# MSS_CTRL_MSS_CTRL_50D00000h register map
Vendor: Texas Instruments
Registers are 32-bit, read-write, reset values left out (the file's numbers can be read two ways) unless marked. A register's access mark holds for its fields unless they carry their own. Offsets are as the file gives them; [hi:lo] are bit positions.

## MSS_CTRL (part 6 of 6)
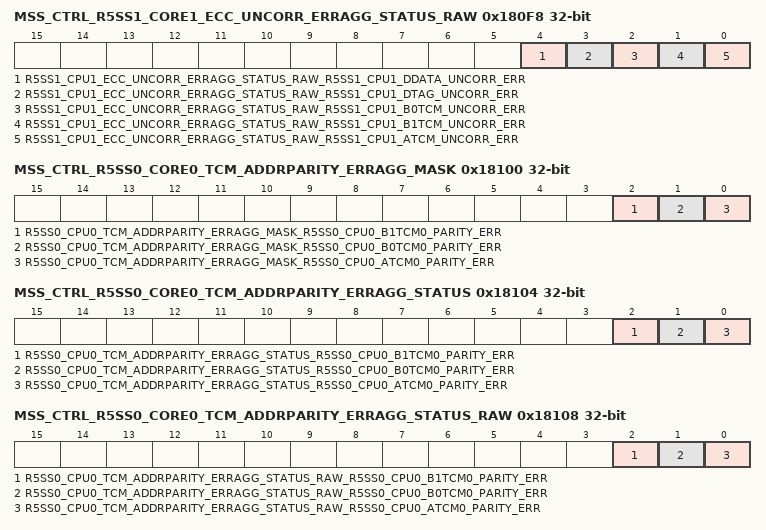
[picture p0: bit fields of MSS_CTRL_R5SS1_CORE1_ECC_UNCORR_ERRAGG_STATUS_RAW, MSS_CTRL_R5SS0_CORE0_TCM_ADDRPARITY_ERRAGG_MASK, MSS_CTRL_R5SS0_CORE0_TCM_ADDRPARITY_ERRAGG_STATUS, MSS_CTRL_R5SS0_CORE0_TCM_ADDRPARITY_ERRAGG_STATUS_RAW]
0x180F8 MSS_CTRL_R5SS1_CORE1_ECC_UNCORR_ERRAGG_STATUS_RAW
  [4] R5SS1_CPU1_ECC_UNCORR_ERRAGG_STATUS_RAW_R5SS1_CPU1_DDATA_UNCORR_ERR — Raw Status of Interrupt from correctable error of corresponding CPUSet only if Interupt is unmasked in corresponding R5SS*_CPU*_ECC_UNCORR_ERRAGG_MASK registerWrie 0x1 to clear this interrupt.
  [3] R5SS1_CPU1_ECC_UNCORR_ERRAGG_STATUS_RAW_R5SS1_CPU1_DTAG_UNCORR_ERR — Raw Status of Interrupt from correctable error of corresponding CPUSet only if Interupt is unmasked in corresponding R5SS*_CPU*_ECC_UNCORR_ERRAGG_MASK registerWrie 0x1 to clear this interrupt.
  [2] R5SS1_CPU1_ECC_UNCORR_ERRAGG_STATUS_RAW_R5SS1_CPU1_B0TCM_UNCORR_ERR — Raw Status of Interrupt from correctable error of corresponding CPUSet only if Interupt is unmasked in corresponding R5SS*_CPU*_ECC_UNCORR_ERRAGG_MASK registerWrie 0x1 to clear this interrupt.
  [1] R5SS1_CPU1_ECC_UNCORR_ERRAGG_STATUS_RAW_R5SS1_CPU1_B1TCM_UNCORR_ERR — Raw Status of Interrupt from correctable error of corresponding CPUSet only if Interupt is unmasked in corresponding R5SS*_CPU*_ECC_UNCORR_ERRAGG_MASK registerWrie 0x1 to clear this interrupt.
  [0] R5SS1_CPU1_ECC_UNCORR_ERRAGG_STATUS_RAW_R5SS1_CPU1_ATCM_UNCORR_ERR — Raw Status of Interrupt from correctable error of corresponding CPUSet only if Interupt is unmasked in corresponding R5SS*_CPU*_ECC_UNCORR_ERRAGG_MASK registerWrie 0x1 to clear this interrupt.
0x18100 MSS_CTRL_R5SS0_CORE0_TCM_ADDRPARITY_ERRAGG_MASK
  [2] R5SS0_CPU0_TCM_ADDRPARITY_ERRAGG_MASK_R5SS0_CPU0_B1TCM0_PARITY_ERR — Mask Interrupt for address parity error s to aggregated Interrupt of corresponding CPU1'b1 : Interrupt is Masked1'b0 : Interrupt is Unmasked
  [1] R5SS0_CPU0_TCM_ADDRPARITY_ERRAGG_MASK_R5SS0_CPU0_B0TCM0_PARITY_ERR — Mask Interrupt for address parity error s to aggregated Interrupt of corresponding CPU1'b1 : Interrupt is Masked1'b0 : Interrupt is Unmasked
  [0] R5SS0_CPU0_TCM_ADDRPARITY_ERRAGG_MASK_R5SS0_CPU0_ATCM0_PARITY_ERR — Mask Interrupt for address parity error s to aggregated Interrupt of corresponding CPU1'b1 : Interrupt is Masked1'b0 : Interrupt is Unmasked
0x18104 MSS_CTRL_R5SS0_CORE0_TCM_ADDRPARITY_ERRAGG_STATUS
  [2] R5SS0_CPU0_TCM_ADDRPARITY_ERRAGG_STATUS_R5SS0_CPU0_B1TCM0_PARITY_ERR — Status of Interrupt from address parity error of corresponding CPU*_TCM_ADDRPARITY_ERRAGG_MASK registerWrie 0x1 to clear this interrupt.
  [1] R5SS0_CPU0_TCM_ADDRPARITY_ERRAGG_STATUS_R5SS0_CPU0_B0TCM0_PARITY_ERR — Status of Interrupt from address parity error of corresponding CPU*_TCM_ADDRPARITY_ERRAGG_MASK registerWrie 0x1 to clear this interrupt.
  [0] R5SS0_CPU0_TCM_ADDRPARITY_ERRAGG_STATUS_R5SS0_CPU0_ATCM0_PARITY_ERR — Status of Interrupt from address parity error of corresponding CPU*_TCM_ADDRPARITY_ERRAGG_MASK registerWrie 0x1 to clear this interrupt.
0x18108 MSS_CTRL_R5SS0_CORE0_TCM_ADDRPARITY_ERRAGG_STATUS_RAW
  [2] R5SS0_CPU0_TCM_ADDRPARITY_ERRAGG_STATUS_RAW_R5SS0_CPU0_B1TCM0_PARITY_ERR — Raw Status of Interrupt from address parity error of corresponding CPU*_TCM_ADDRPARITY_ERRAGG_MASK registerWrie 0x1 to clear this interrupt.
  [1] R5SS0_CPU0_TCM_ADDRPARITY_ERRAGG_STATUS_RAW_R5SS0_CPU0_B0TCM0_PARITY_ERR — Raw Status of Interrupt from address parity error of corresponding CPU*_TCM_ADDRPARITY_ERRAGG_MASK registerWrie 0x1 to clear this interrupt.
  [0] R5SS0_CPU0_TCM_ADDRPARITY_ERRAGG_STATUS_RAW_R5SS0_CPU0_ATCM0_PARITY_ERR — Raw Status of Interrupt from address parity error of corresponding CPU*_TCM_ADDRPARITY_ERRAGG_MASK registerWrie 0x1 to clear this interrupt.
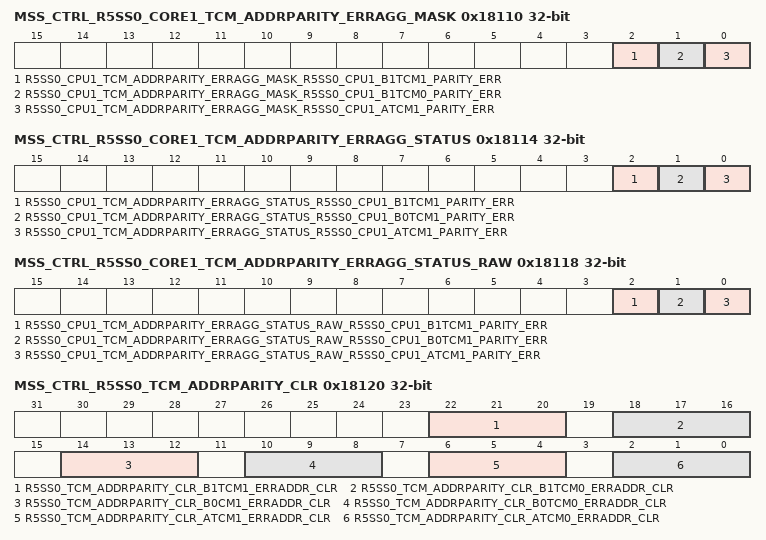
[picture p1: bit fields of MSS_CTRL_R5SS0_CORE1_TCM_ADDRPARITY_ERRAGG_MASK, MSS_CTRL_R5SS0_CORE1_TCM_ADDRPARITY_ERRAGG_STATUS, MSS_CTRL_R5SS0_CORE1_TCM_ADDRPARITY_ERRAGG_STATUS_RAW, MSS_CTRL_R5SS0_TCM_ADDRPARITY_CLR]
0x18110 MSS_CTRL_R5SS0_CORE1_TCM_ADDRPARITY_ERRAGG_MASK
  [2] R5SS0_CPU1_TCM_ADDRPARITY_ERRAGG_MASK_R5SS0_CPU1_B1TCM1_PARITY_ERR — Mask Interrupt for address parity error s to aggregated Interrupt of corresponding CPU1'b1 : Interrupt is Masked1'b0 : Interrupt is Unmasked
  [1] R5SS0_CPU1_TCM_ADDRPARITY_ERRAGG_MASK_R5SS0_CPU1_B1TCM0_PARITY_ERR — Mask Interrupt for address parity error s to aggregated Interrupt of corresponding CPU1'b1 : Interrupt is Masked1'b0 : Interrupt is Unmasked
  [0] R5SS0_CPU1_TCM_ADDRPARITY_ERRAGG_MASK_R5SS0_CPU1_ATCM1_PARITY_ERR — Mask Interrupt for address parity error s to aggregated Interrupt of corresponding CPU1'b1 : Interrupt is Masked1'b0 : Interrupt is Unmasked
0x18114 MSS_CTRL_R5SS0_CORE1_TCM_ADDRPARITY_ERRAGG_STATUS
  [2] R5SS0_CPU1_TCM_ADDRPARITY_ERRAGG_STATUS_R5SS0_CPU1_B1TCM1_PARITY_ERR — Status of Interrupt from address parity error of corresponding CPU*_TCM_ADDRPARITY_ERRAGG_MASK registerWrie 0x1 to clear this interrupt.
  [1] R5SS0_CPU1_TCM_ADDRPARITY_ERRAGG_STATUS_R5SS0_CPU1_B0TCM1_PARITY_ERR — Status of Interrupt from address parity error of corresponding CPU*_TCM_ADDRPARITY_ERRAGG_MASK registerWrie 0x1 to clear this interrupt.
  [0] R5SS0_CPU1_TCM_ADDRPARITY_ERRAGG_STATUS_R5SS0_CPU1_ATCM1_PARITY_ERR — Status of Interrupt from address parity error of corresponding CPU*_TCM_ADDRPARITY_ERRAGG_MASK registerWrie 0x1 to clear this interrupt.
0x18118 MSS_CTRL_R5SS0_CORE1_TCM_ADDRPARITY_ERRAGG_STATUS_RAW
  [2] R5SS0_CPU1_TCM_ADDRPARITY_ERRAGG_STATUS_RAW_R5SS0_CPU1_B1TCM1_PARITY_ERR — Raw Status of Interrupt from address parity error of corresponding CPU*_TCM_ADDRPARITY_ERRAGG_MASK registerWrie 0x1 to clear this interrupt.
  [1] R5SS0_CPU1_TCM_ADDRPARITY_ERRAGG_STATUS_RAW_R5SS0_CPU1_B0TCM1_PARITY_ERR — Raw Status of Interrupt from address parity error of corresponding CPU*_TCM_ADDRPARITY_ERRAGG_MASK registerWrie 0x1 to clear this interrupt.
  [0] R5SS0_CPU1_TCM_ADDRPARITY_ERRAGG_STATUS_RAW_R5SS0_CPU1_ATCM1_PARITY_ERR — Raw Status of Interrupt from address parity error of corresponding CPU*_TCM_ADDRPARITY_ERRAGG_MASK registerWrie 0x1 to clear this interrupt.
0x18120 MSS_CTRL_R5SS0_TCM_ADDRPARITY_CLR
  [22:20] R5SS0_TCM_ADDRPARITY_CLR_B1TCM1_ERRADDR_CLR — Write pulse bit field:Writing 3'b111 clears the Address latched after parity error for B1TCM of CR5B
  [18:16] R5SS0_TCM_ADDRPARITY_CLR_B1TCM0_ERRADDR_CLR — Write pulse bit field:Writing 3'b111 clears the Address latched after parity error for B1TCM of CR5A
  [14:12] R5SS0_TCM_ADDRPARITY_CLR_B0CM1_ERRADDR_CLR — Write pulse bit field:Writing 3'b111 clears the Address latched after parity error for B0TCM of CR5B
  [10:8] R5SS0_TCM_ADDRPARITY_CLR_B0TCM0_ERRADDR_CLR — Write pulse bit field:Writing 3'b111 clears the Address latched after parity error for B0TCM of CR5A
  [6:4] R5SS0_TCM_ADDRPARITY_CLR_ATCM1_ERRADDR_CLR — Write pulse bit field:Writing 3'b111 clears the Address latched after parity error for ATCM of CR5B
  [2:0] R5SS0_TCM_ADDRPARITY_CLR_ATCM0_ERRADDR_CLR — Pulse bit-field Writing 3'b111 clears the Address latched after parity error for ATCM of CR5A
0x18124 MSS_CTRL_R5SS0_CORE0_ADDRPARITY_ERR_ATCM ro
  [19:0] R5SS0_CORE0_ADDRPARITY_ERR_ATCM_ADDR — Address lathched when parity error is occurred for ATCM of CR5A
0x18128 MSS_CTRL_R5SS0_CORE1_ADDRPARITY_ERR_ATCM ro
  [19:0] R5SS0_CORE1_ADDRPARITY_ERR_ATCM_ADDR — Address lathched when parity error is occurred for ATCM of CR5B
0x1812C MSS_CTRL_R5SS0_CORE0_ERR_ADDRPARITY_B0TCM ro
  [19:0] R5SS0_CORE0_ERR_ADDRPARITY_B0TCM_ADDR — Address lathched when parity error is occurred for B0TCM of CR5A
0x18130 MSS_CTRL_R5SS0_CORE1_ERR_ADDRPARITY_B0TCM ro
  [19:0] R5SS0_CORE1_ERR_ADDRPARITY_B0TCM_ADDR — Address lathched when parity error is occurred for B0TCM of CR5B
0x18134 MSS_CTRL_R5SS0_CORE0_ERR_ADDRPARITY_B1TCM ro
  [19:0] R5SS0_CORE0_ERR_ADDRPARITY_B1TCM_ADDR — Address lathched when parity error is occurred for B1TCM of CR5A
0x18138 MSS_CTRL_R5SS0_CORE1_ERR_ADDRPARITY_B1TCM ro
  [19:0] R5SS0_CORE1_ERR_ADDRPARITY_B1TCM_ADDR — Address lathched when parity error is occurred for B1TCM of CR5B
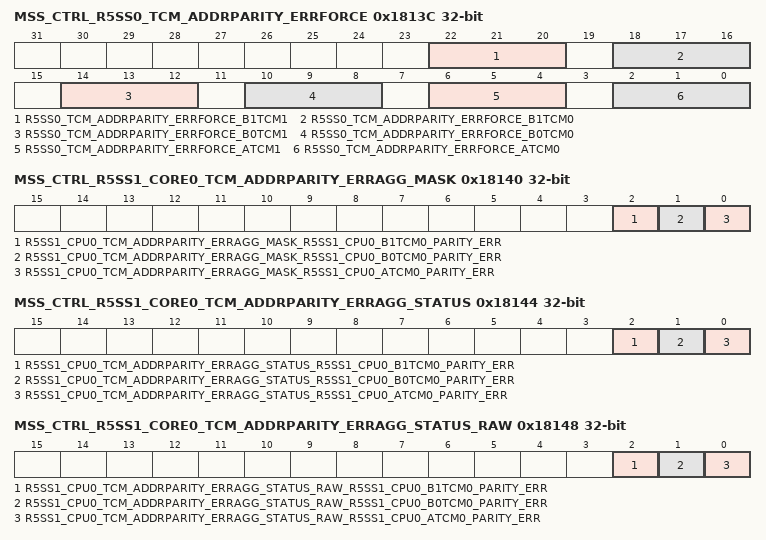
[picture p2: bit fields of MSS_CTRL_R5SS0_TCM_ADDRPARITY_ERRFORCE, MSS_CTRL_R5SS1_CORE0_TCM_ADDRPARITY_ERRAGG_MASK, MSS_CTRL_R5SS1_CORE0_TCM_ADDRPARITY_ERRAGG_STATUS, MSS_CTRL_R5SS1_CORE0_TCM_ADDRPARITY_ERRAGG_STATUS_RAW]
0x1813C MSS_CTRL_R5SS0_TCM_ADDRPARITY_ERRFORCE
  [22:20] R5SS0_TCM_ADDRPARITY_ERRFORCE_B1TCM1 — Write pulse bit field:Writing 3'b111 forces a parity error for B1TCM of CR5B
  [18:16] R5SS0_TCM_ADDRPARITY_ERRFORCE_B1TCM0 — Write pulse bit field:Writing 3'b111 forces a parity error for B1TCM of CR5A
  [14:12] R5SS0_TCM_ADDRPARITY_ERRFORCE_B0TCM1 — Write pulse bit field:Writing 3'b111 forces a parity error for B0TCM of CR5B
  [10:8] R5SS0_TCM_ADDRPARITY_ERRFORCE_B0TCM0 — Write pulse bit field:Writing 3'b111 forces a parity error for B0TCM of CR5A
  [6:4] R5SS0_TCM_ADDRPARITY_ERRFORCE_ATCM1 — Write pulse bit field:Writing 3'b111 forces a parity error for ATCM of CR5B
  [2:0] R5SS0_TCM_ADDRPARITY_ERRFORCE_ATCM0 — Write pulse bit field:Writing 3'b111 forces a parity error for ATCM of CR5A
0x18140 MSS_CTRL_R5SS1_CORE0_TCM_ADDRPARITY_ERRAGG_MASK
  [2] R5SS1_CPU0_TCM_ADDRPARITY_ERRAGG_MASK_R5SS1_CPU0_B1TCM0_PARITY_ERR — Mask Interrupt for address parity error s to aggregated Interrupt of corresponding CPU1'b1 : Interrupt is Masked1'b0 : Interrupt is Unmasked
  [1] R5SS1_CPU0_TCM_ADDRPARITY_ERRAGG_MASK_R5SS1_CPU0_B0TCM0_PARITY_ERR — Mask Interrupt for address parity error s to aggregated Interrupt of corresponding CPU1'b1 : Interrupt is Masked1'b0 : Interrupt is Unmasked
  [0] R5SS1_CPU0_TCM_ADDRPARITY_ERRAGG_MASK_R5SS1_CPU0_ATCM0_PARITY_ERR — Mask Interrupt for address parity error s to aggregated Interrupt of corresponding CPU1'b1 : Interrupt is Masked1'b0 : Interrupt is Unmasked
0x18144 MSS_CTRL_R5SS1_CORE0_TCM_ADDRPARITY_ERRAGG_STATUS
  [2] R5SS1_CPU0_TCM_ADDRPARITY_ERRAGG_STATUS_R5SS1_CPU0_B1TCM0_PARITY_ERR — Status of Interrupt from address parity error of corresponding CPU*_TCM_ADDRPARITY_ERRAGG_MASK registerWrie 0x1 to clear this interrupt.
  [1] R5SS1_CPU0_TCM_ADDRPARITY_ERRAGG_STATUS_R5SS1_CPU0_B0TCM0_PARITY_ERR — Status of Interrupt from address parity error of corresponding CPU*_TCM_ADDRPARITY_ERRAGG_MASK registerWrie 0x1 to clear this interrupt.
  [0] R5SS1_CPU0_TCM_ADDRPARITY_ERRAGG_STATUS_R5SS1_CPU0_ATCM0_PARITY_ERR — Status of Interrupt from address parity error of corresponding CPU*_TCM_ADDRPARITY_ERRAGG_MASK registerWrie 0x1 to clear this interrupt.
0x18148 MSS_CTRL_R5SS1_CORE0_TCM_ADDRPARITY_ERRAGG_STATUS_RAW
  [2] R5SS1_CPU0_TCM_ADDRPARITY_ERRAGG_STATUS_RAW_R5SS1_CPU0_B1TCM0_PARITY_ERR — Raw Status of Interrupt from address parity error of corresponding CPU*_TCM_ADDRPARITY_ERRAGG_MASK registerWrie 0x1 to clear this interrupt.
  [1] R5SS1_CPU0_TCM_ADDRPARITY_ERRAGG_STATUS_RAW_R5SS1_CPU0_B0TCM0_PARITY_ERR — Raw Status of Interrupt from address parity error of corresponding CPU*_TCM_ADDRPARITY_ERRAGG_MASK registerWrie 0x1 to clear this interrupt.
  [0] R5SS1_CPU0_TCM_ADDRPARITY_ERRAGG_STATUS_RAW_R5SS1_CPU0_ATCM0_PARITY_ERR — Raw Status of Interrupt from address parity error of corresponding CPU*_TCM_ADDRPARITY_ERRAGG_MASK registerWrie 0x1 to clear this interrupt.
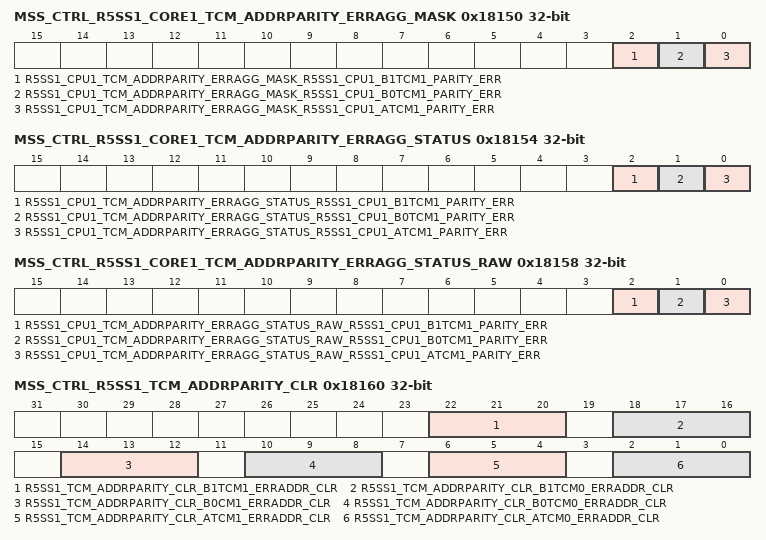
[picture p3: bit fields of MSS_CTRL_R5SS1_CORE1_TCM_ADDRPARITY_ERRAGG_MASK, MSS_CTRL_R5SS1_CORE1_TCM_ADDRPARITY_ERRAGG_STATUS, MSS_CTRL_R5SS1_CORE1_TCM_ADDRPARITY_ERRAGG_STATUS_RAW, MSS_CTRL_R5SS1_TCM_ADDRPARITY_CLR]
0x18150 MSS_CTRL_R5SS1_CORE1_TCM_ADDRPARITY_ERRAGG_MASK
  [2] R5SS1_CPU1_TCM_ADDRPARITY_ERRAGG_MASK_R5SS1_CPU1_B1TCM1_PARITY_ERR — Mask Interrupt for address parity error s to aggregated Interrupt of corresponding CPU1'b1 : Interrupt is Masked1'b0 : Interrupt is Unmasked
  [1] R5SS1_CPU1_TCM_ADDRPARITY_ERRAGG_MASK_R5SS1_CPU1_B0TCM1_PARITY_ERR — Mask Interrupt for address parity error s to aggregated Interrupt of corresponding CPU1'b1 : Interrupt is Masked1'b0 : Interrupt is Unmasked
  [0] R5SS1_CPU1_TCM_ADDRPARITY_ERRAGG_MASK_R5SS1_CPU1_ATCM1_PARITY_ERR — Mask Interrupt for address parity error s to aggregated Interrupt of corresponding CPU1'b1 : Interrupt is Masked1'b0 : Interrupt is Unmasked
0x18154 MSS_CTRL_R5SS1_CORE1_TCM_ADDRPARITY_ERRAGG_STATUS
  [2] R5SS1_CPU1_TCM_ADDRPARITY_ERRAGG_STATUS_R5SS1_CPU1_B1TCM1_PARITY_ERR — Status of Interrupt from address parity error of corresponding CPU*_TCM_ADDRPARITY_ERRAGG_MASK registerWrie 0x1 to clear this interrupt.
  [1] R5SS1_CPU1_TCM_ADDRPARITY_ERRAGG_STATUS_R5SS1_CPU1_B0TCM1_PARITY_ERR — Status of Interrupt from address parity error of corresponding CPU*_TCM_ADDRPARITY_ERRAGG_MASK registerWrie 0x1 to clear this interrupt.
  [0] R5SS1_CPU1_TCM_ADDRPARITY_ERRAGG_STATUS_R5SS1_CPU1_ATCM1_PARITY_ERR — Status of Interrupt from address parity error of corresponding CPU*_TCM_ADDRPARITY_ERRAGG_MASK registerWrie 0x1 to clear this interrupt.
0x18158 MSS_CTRL_R5SS1_CORE1_TCM_ADDRPARITY_ERRAGG_STATUS_RAW
  [2] R5SS1_CPU1_TCM_ADDRPARITY_ERRAGG_STATUS_RAW_R5SS1_CPU1_B1TCM1_PARITY_ERR — Raw Status of Interrupt from address parity error of corresponding CPU*_TCM_ADDRPARITY_ERRAGG_MASK registerWrie 0x1 to clear this interrupt.
  [1] R5SS1_CPU1_TCM_ADDRPARITY_ERRAGG_STATUS_RAW_R5SS1_CPU1_B0TCM1_PARITY_ERR — Raw Status of Interrupt from address parity error of corresponding CPU*_TCM_ADDRPARITY_ERRAGG_MASK registerWrie 0x1 to clear this interrupt.
  [0] R5SS1_CPU1_TCM_ADDRPARITY_ERRAGG_STATUS_RAW_R5SS1_CPU1_ATCM1_PARITY_ERR — Raw Status of Interrupt from address parity error of corresponding CPU*_TCM_ADDRPARITY_ERRAGG_MASK registerWrie 0x1 to clear this interrupt.
0x18160 MSS_CTRL_R5SS1_TCM_ADDRPARITY_CLR
  [22:20] R5SS1_TCM_ADDRPARITY_CLR_B1TCM1_ERRADDR_CLR — Write pulse bit field:Writing 3'b111 clears the Address latched after parity error for B1TCM of CR5B
  [18:16] R5SS1_TCM_ADDRPARITY_CLR_B1TCM0_ERRADDR_CLR — Write pulse bit field:Writing 3'b111 clears the Address latched after parity error for B1TCM of CR5A
  [14:12] R5SS1_TCM_ADDRPARITY_CLR_B0CM1_ERRADDR_CLR — Write pulse bit field:Writing 3'b111 clears the Address latched after parity error for B0TCM of CR5B
  [10:8] R5SS1_TCM_ADDRPARITY_CLR_B0TCM0_ERRADDR_CLR — Write pulse bit field:Writing 3'b111 clears the Address latched after parity error for B0TCM of CR5A
  [6:4] R5SS1_TCM_ADDRPARITY_CLR_ATCM1_ERRADDR_CLR — Write pulse bit field:Writing 3'b111 clears the Address latched after parity error for ATCM of CR5B
  [2:0] R5SS1_TCM_ADDRPARITY_CLR_ATCM0_ERRADDR_CLR — Pulse bit-field Writing 3'b111 clears the Address latched after parity error for ATCM of CR5A
0x18164 MSS_CTRL_R5SS1_CORE0_ADDRPARITY_ERR_ATCM ro
  [19:0] R5SS1_CORE0_ADDRPARITY_ERR_ATCM_ADDR — Address lathched when parity error is occurred for ATCM of CR5A
0x18168 MSS_CTRL_R5SS1_CORE1_ADDRPARITY_ERR_ATCM ro
  [19:0] R5SS1_CORE1_ADDRPARITY_ERR_ATCM_ADDR — Address lathched when parity error is occurred for ATCM of CR5B
0x1816C MSS_CTRL_R5SS1_CORE0_ERR_ADDRPARITY_B0TCM ro
  [19:0] R5SS1_CORE0_ERR_ADDRPARITY_B0TCM_ADDR — Address lathched when parity error is occurred for B0TCM of CR5A
0x18170 MSS_CTRL_R5SS1_CORE1_ERR_ADDRPARITY_B0TCM ro
  [19:0] R5SS1_CORE1_ERR_ADDRPARITY_B0TCM_ADDR — Address lathched when parity error is occurred for B0TCM of CR5B
0x18174 MSS_CTRL_R5SS1_CORE0_ERR_ADDRPARITY_B1TCM ro
  [19:0] R5SS1_CORE0_ERR_ADDRPARITY_B1TCM_ADDR — Address lathched when parity error is occurred for B1TCM of CR5A
0x18178 MSS_CTRL_R5SS1_CORE1_ERR_ADDRPARITY_B1TCM ro
  [19:0] R5SS1_CORE1_ERR_ADDRPARITY_B1TCM_ADDR — Address lathched when parity error is occurred for B1TCM of CR5B
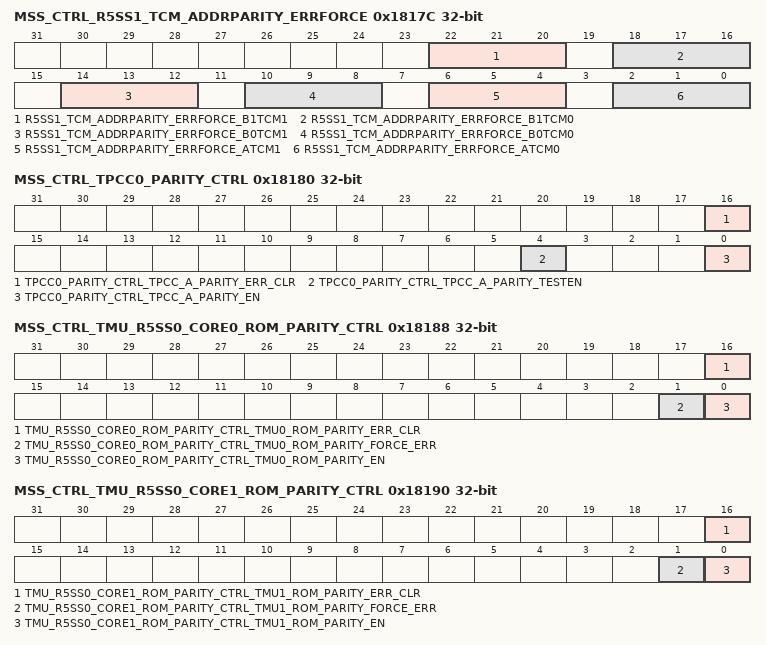
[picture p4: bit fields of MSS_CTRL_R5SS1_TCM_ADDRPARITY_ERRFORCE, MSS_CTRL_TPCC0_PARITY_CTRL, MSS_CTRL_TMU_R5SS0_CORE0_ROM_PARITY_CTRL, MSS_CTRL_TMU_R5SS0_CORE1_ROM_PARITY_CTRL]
0x1817C MSS_CTRL_R5SS1_TCM_ADDRPARITY_ERRFORCE
  [22:20] R5SS1_TCM_ADDRPARITY_ERRFORCE_B1TCM1 — Write pulse bit field:Writing 3'b111 forces a parity error for B1TCM of CR5B
  [18:16] R5SS1_TCM_ADDRPARITY_ERRFORCE_B1TCM0 — Write pulse bit field:Writing 3'b111 forces a parity error for B1TCM of CR5A
  [14:12] R5SS1_TCM_ADDRPARITY_ERRFORCE_B0TCM1 — Write pulse bit field:Writing 3'b111 forces a parity error for B0TCM of CR5B
  [10:8] R5SS1_TCM_ADDRPARITY_ERRFORCE_B0TCM0 — Write pulse bit field:Writing 3'b111 forces a parity error for B0TCM of CR5A
  [6:4] R5SS1_TCM_ADDRPARITY_ERRFORCE_ATCM1 — Write pulse bit field:Writing 3'b111 forces a parity error for ATCM of CR5B
  [2:0] R5SS1_TCM_ADDRPARITY_ERRFORCE_ATCM0 — Write pulse bit field:Writing 3'b111 forces a parity error for ATCM of CR5A
0x18180 MSS_CTRL_TPCC0_PARITY_CTRL
  [16] TPCC0_PARITY_CTRL_TPCC_A_PARITY_ERR_CLR — Write pulse bit field:parity clear bit. Writing 1'b1 will clear the tpcc_a_parity_addr
  [4] TPCC0_PARITY_CTRL_TPCC_A_PARITY_TESTEN — parity test enable for tpcc a
  [0] TPCC0_PARITY_CTRL_TPCC_A_PARITY_EN — Writing 1'b1 enables parity for TPCC_A
0x18184 MSS_CTRL_TPCC0_PARITY_STATUS ro
  [8:0] TPCC0_PARITY_STATUS_TPCC_A_PARITY_ADDR — Address where parity error happened for tpcca
0x18188 MSS_CTRL_TMU_R5SS0_CORE0_ROM_PARITY_CTRL
  [16] TMU_R5SS0_CORE0_ROM_PARITY_CTRL_TMU0_ROM_PARITY_ERR_CLR — Write pulse bit field:parity clear bit. Writing 1'b1 will clear the tmu0_rom_parity_err_addr
  [1] TMU_R5SS0_CORE0_ROM_PARITY_CTRL_TMU0_ROM_PARITY_FORCE_ERR — Force parity error on the read interface
  [0] TMU_R5SS0_CORE0_ROM_PARITY_CTRL_TMU0_ROM_PARITY_EN — Writing 1'b1 enables parity for TMU0
0x1818C MSS_CTRL_TMU_R5SS0_CORE0_ROM_PARITY_STATUS ro
  [10:0] TMU_R5SS0_CORE0_ROM_PARITY_STATUS_TMU0_ROM_PARITY_ERR_ADDR — Address where parity error happened for tmu0
0x18190 MSS_CTRL_TMU_R5SS0_CORE1_ROM_PARITY_CTRL
  [16] TMU_R5SS0_CORE1_ROM_PARITY_CTRL_TMU1_ROM_PARITY_ERR_CLR — Write pulse bit field:parity clear bit. Writing 1'b1 will clear the tmu1_rom_parity_err_addr
  [1] TMU_R5SS0_CORE1_ROM_PARITY_CTRL_TMU1_ROM_PARITY_FORCE_ERR — Force parity error on the read interface
  [0] TMU_R5SS0_CORE1_ROM_PARITY_CTRL_TMU1_ROM_PARITY_EN — Writing 1'b1 enables parity for TMU1
0x18194 MSS_CTRL_TMU_R5SS0_CORE1_ROM_PARITY_STATUS ro
  [10:0] TMU_R5SS0_CORE1_ROM_PARITY_STATUS_TMU1_ROM_PARITY_ERR_ADDR — Address where parity error happened for tmu1
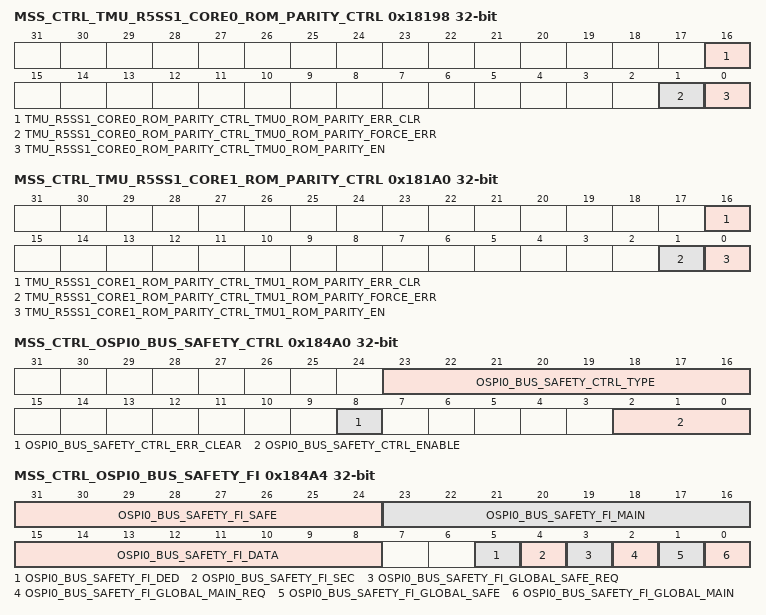
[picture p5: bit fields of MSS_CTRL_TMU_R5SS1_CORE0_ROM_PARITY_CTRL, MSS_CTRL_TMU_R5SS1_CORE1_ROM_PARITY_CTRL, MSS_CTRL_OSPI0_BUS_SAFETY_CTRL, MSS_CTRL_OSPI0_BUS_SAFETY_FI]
0x18198 MSS_CTRL_TMU_R5SS1_CORE0_ROM_PARITY_CTRL
  [16] TMU_R5SS1_CORE0_ROM_PARITY_CTRL_TMU0_ROM_PARITY_ERR_CLR — Write pulse bit field:parity clear bit. Writing 1'b1 will clear the tmu0_rom_parity_err_addr
  [1] TMU_R5SS1_CORE0_ROM_PARITY_CTRL_TMU0_ROM_PARITY_FORCE_ERR — Force parity error on the read interface
  [0] TMU_R5SS1_CORE0_ROM_PARITY_CTRL_TMU0_ROM_PARITY_EN — Writing 1'b1 enables parity for TMU0
0x1819C MSS_CTRL_TMU_R5SS1_CORE0_ROM_PARITY_STATUS ro
  [10:0] TMU_R5SS1_CORE0_ROM_PARITY_STATUS_TMU0_ROM_PARITY_ERR_ADDR — Address where parity error happened for tmu0
0x181A0 MSS_CTRL_TMU_R5SS1_CORE1_ROM_PARITY_CTRL
  [16] TMU_R5SS1_CORE1_ROM_PARITY_CTRL_TMU1_ROM_PARITY_ERR_CLR — Write pulse bit field:parity clear bit. Writing 1'b1 will clear the tmu1_rom_parity_err_addr
  [1] TMU_R5SS1_CORE1_ROM_PARITY_CTRL_TMU1_ROM_PARITY_FORCE_ERR — Force parity error on the read interface
  [0] TMU_R5SS1_CORE1_ROM_PARITY_CTRL_TMU1_ROM_PARITY_EN — Writing 1'b1 enables parity for TMU1
0x181A4 MSS_CTRL_TMU_R5SS1_CORE1_ROM_PARITY_STATUS ro
  [10:0] TMU_R5SS1_CORE1_ROM_PARITY_STATUS_TMU1_ROM_PARITY_ERR_ADDR — Address where parity error happened for tmu1
0x184A0 MSS_CTRL_OSPI0_BUS_SAFETY_CTRL access per field
  [23:16] OSPI0_BUS_SAFETY_CTRL_TYPE ro — This bitfield gives a top level idea of the available bus [cmd,wr,ws,rd] for the particular Target/Initiator and whether it follows the VBUS protocol or not. Bit 0 - 1'b1 indicates the Command bus is implemented to this target/initiator else it is set to 1'b0. Bit 1 - 1'b1 indicates the write bus is implemented to this target/initiator else it is set to 1'b0. Bit 2 - 1'b1 indicates the write status bus is implemented to this target/initiator else it is set to 1'b0. Bit 3 - 1'b1 indicates the read bus is implemented to this target/initiator else it is set to 1'b0. Bit 4 - 1'b0 indicates the port follows the VBUS protocol else it is set to 1'b1. Bits 5-7 are set to 3'b000.
  [8] OSPI0_BUS_SAFETY_CTRL_ERR_CLEAR rw — Set this bit to 1'b1 to clear the error status for this port
  [2:0] OSPI0_BUS_SAFETY_CTRL_ENABLE rw — Set this bit to 3'b111 to enable the safety configuration for this port. Set this bit to 3'b000 to disable the safety configuration for this port.
0x184A4 MSS_CTRL_OSPI0_BUS_SAFETY_FI
  [31:24] OSPI0_BUS_SAFETY_FI_SAFE — This bitfield is used to inject fault on Read, write, command and request bus on the safe Interconnect. Bit 0 - Set this bit to inject fault on the Command bus. Bit 1 - Set this bit to inject fault on theWrite bus. Bit 2 - Set this bit to inject fault on the Write Status bus.Bit 3 - Set this bit to inject fault on the Read bus. Bit 7- Set this bit to inject fault on the corresponding request bus.
  [23:16] OSPI0_BUS_SAFETY_FI_MAIN — This bitfield is used to inject fault on Read, write, command and request bus on the main Interconnect.Bit 0 - Set this bit to inject fault on the Command bus. Bit 1 - Set this bit to inject fault on theWrite bus. Bit 2 - Set this bit to inject fault on the Write Status bus.Bit 3 - Set this bit to inject fault on the Read bus. Bit 7- Set this bit to inject fault on the corresponding request bus.
  [15:8] OSPI0_BUS_SAFETY_FI_DATA — Set bit 0 to 1'b1 to inject sec and ded faults on [31:0] bits of data bus.Set bit 1 to 1'b1 to inject sec and ded faults on [64:32] bits of data bus.
  [5] OSPI0_BUS_SAFETY_FI_DED — Set this bit to 1'b1 inject ded error on data at this port
  [4] OSPI0_BUS_SAFETY_FI_SEC — Set this bit to 1'b1 to inject sec error on data at this port
  [3] OSPI0_BUS_SAFETY_FI_GLOBAL_SAFE_REQ — Set this bit 1'b1 to inject fault for request signals on Safe Interconnect.
  [2] OSPI0_BUS_SAFETY_FI_GLOBAL_MAIN_REQ — Set this bit to 1'b1 to inject fault for request signals on main Interconnect.
  [1] OSPI0_BUS_SAFETY_FI_GLOBAL_SAFE — This is a global safe Fault injection signal. Set this bit to inject fault on all the safety buses of the safe interconnect except req signal. Writing a 1'b1 injects fault on interconnect.
  [0] OSPI0_BUS_SAFETY_FI_GLOBAL_MAIN — This is a global main Fault injection signal. Set this bit to inject fault on all the buses of the main interconnect except req signal. Writing a 1'b1 injects fault on interconnect.
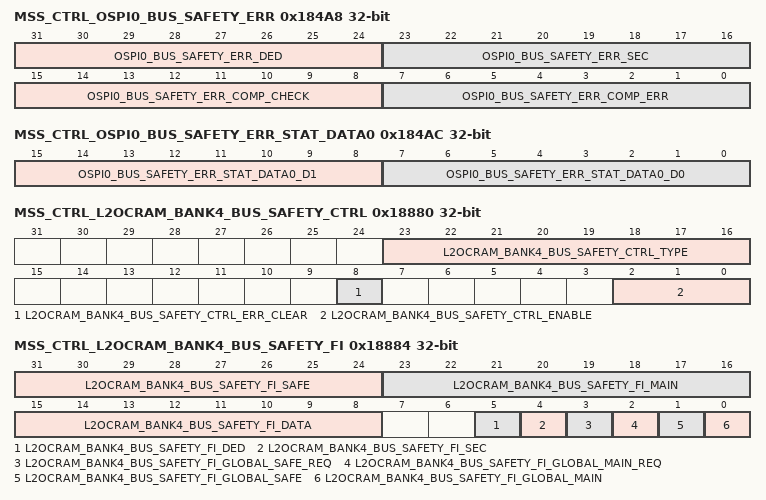
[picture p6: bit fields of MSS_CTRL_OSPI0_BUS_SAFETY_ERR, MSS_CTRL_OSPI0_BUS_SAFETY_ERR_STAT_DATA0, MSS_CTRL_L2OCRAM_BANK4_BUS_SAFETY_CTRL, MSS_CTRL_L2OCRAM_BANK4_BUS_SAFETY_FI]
0x184A8 MSS_CTRL_OSPI0_BUS_SAFETY_ERR ro
  [31:24] OSPI0_BUS_SAFETY_ERR_DED — This flag signals detection of dual error in Data at this port.Flag is generted for 32 bit segment of Data BusBit 0 - 1'b1 indicates ded on [31:0] bit of Data busBit 1 - 1'b1 indicates ded on [63:32] bit of Data busBit [7:2] - Unused. Set to 1'b0
  [23:16] OSPI0_BUS_SAFETY_ERR_SEC — This flag signals detection of single error in Data at this port. Flag is generted for 32 bit segment of Data BusBit 0 - 1'b1 indicates sec on [31:0] bit of Data busBit 1 - 1'b1 indicates sec on [63:32] bit of Data busBit [7:2] - Unused. Set to 1'b0
  [15:8] OSPI0_BUS_SAFETY_ERR_COMP_CHECK — This is used to verify the proper functioning of fault Injection on all the buses.1'b1 indicates error in the corresponding Bus has been injected successfully. Bit 0 - This is a Bitwise AND of error compares of all command bus signals.Bit 1 - This is a Bitwise AND of error compares of all write bus signals.Bit 2 - This is a Bitwise AND of error compares of all write status bus signals.Bit 3 - This is a Bitwise AND of error compares of all read bus signals.Bits [7:4] are unused.
  [7:0] OSPI0_BUS_SAFETY_ERR_COMP_ERR — 1'b1 indicates error in the corresponding Bus whenever a fault is detected at any bus signalBit 0 - This is a Bitwise OR of error compares of all command bus signals.Bit 1 - This is a Bitwise OR of error compares of all write bus signals.Bit 2 - This is a Bitwise OR of error compares of all write status bus signals.Bit 3 - This is a Bitwise OR of error compares of all read bus signals.Bits [7:4] are unused.
0x184AC MSS_CTRL_OSPI0_BUS_SAFETY_ERR_STAT_DATA0 ro
  [15:8] OSPI0_BUS_SAFETY_ERR_STAT_DATA0_D1 — Read this bitfield for Comparator status for Higher 32 bits [63:32] of data bus at this port. It represent the position of the flipped bit in case of SEC.
  [7:0] OSPI0_BUS_SAFETY_ERR_STAT_DATA0_D0 — Read this bitfield for Comparator status for lower 32 bits [31:0] of data bus at this port. It represent the position of the flipped bit in case of SEC.
0x184B0 MSS_CTRL_OSPI0_BUS_SAFETY_ERR_STAT_CMD ro
  [31:0] OSPI0_BUS_SAFETY_ERR_STAT_CMD_STAT — Read this bitfield for comparator status for command bus for this port. 1'b1 on any of the bits indicates an error on Command Bus
0x184B4 MSS_CTRL_OSPI0_BUS_SAFETY_ERR_STAT_WRITE ro
  [31:0] OSPI0_BUS_SAFETY_ERR_STAT_WRITE_STAT — Read this bitfield for comparator status for Write bus for this port. 1'b1 at any bit indicates error on Write Bus
0x184B8 MSS_CTRL_OSPI0_BUS_SAFETY_ERR_STAT_READ ro
  [31:0] OSPI0_BUS_SAFETY_ERR_STAT_READ_STAT — Read this bitfield for comapartor status for read signals at this port. 1'b1 on any of the bits indicates an error on Read bus.
0x184BC MSS_CTRL_OSPI0_BUS_SAFETY_ERR_STAT_WRITERESP ro
  [31:0] OSPI0_BUS_SAFETY_ERR_STAT_WRITERESP_STAT — Read this bitfield for comparator status for Write response bus for this port. 1'b1 indicates error on Write Rsponse Bus.
0x18880 MSS_CTRL_L2OCRAM_BANK4_BUS_SAFETY_CTRL access per field
  [23:16] L2OCRAM_BANK4_BUS_SAFETY_CTRL_TYPE ro — This bitfield gives a top level idea of the available bus [cmd,wr,ws,rd] for the particular Target/Initiator and whether it follows the VBUS protocol or not. Bit 0 - 1'b1 indicates the Command bus is implemented to this target/initiator else it is set to 1'b0. Bit 1 - 1'b1 indicates the write bus is implemented to this target/initiator else it is set to 1'b0. Bit 2 - 1'b1 indicates the write status bus is implemented to this target/initiator else it is set to 1'b0. Bit 3 - 1'b1 indicates the read bus is implemented to this target/initiator else it is set to 1'b0. Bit 4 - 1'b0 indicates the port follows the VBUS protocol else it is set to 1'b1. Bits 5-7 are set to 3'b000.
  [8] L2OCRAM_BANK4_BUS_SAFETY_CTRL_ERR_CLEAR rw — Set this bit to 1'b1 to clear the error status for this port
  [2:0] L2OCRAM_BANK4_BUS_SAFETY_CTRL_ENABLE rw — Set this bit to 3'b111 to enable the safety configuration for this port. Set this bit to 3'b000 to disable the safety configuration for this port.
0x18884 MSS_CTRL_L2OCRAM_BANK4_BUS_SAFETY_FI
  [31:24] L2OCRAM_BANK4_BUS_SAFETY_FI_SAFE — This bitfield is used to inject fault on Read, write, command and request bus on the safe Interconnect. Bit 0 - Set this bit to inject fault on the Command bus. Bit 1 - Set this bit to inject fault on theWrite bus. Bit 2 - Set this bit to inject fault on the Write Status bus.Bit 3 - Set this bit to inject fault on the Read bus. Bit 7- Set this bit to inject fault on the corresponding request bus.
  [23:16] L2OCRAM_BANK4_BUS_SAFETY_FI_MAIN — This bitfield is used to inject fault on Read, write, command and request bus on the main Interconnect.Bit 0 - Set this bit to inject fault on the Command bus. Bit 1 - Set this bit to inject fault on theWrite bus. Bit 2 - Set this bit to inject fault on the Write Status bus.Bit 3 - Set this bit to inject fault on the Read bus. Bit 7- Set this bit to inject fault on the corresponding request bus.
  [15:8] L2OCRAM_BANK4_BUS_SAFETY_FI_DATA — Set bit 0 to 1'b1 to inject sec and ded faults on [31:0] bits of data bus.Set bit 1 to 1'b1 to inject sec and ded faults on [64:32] bits of data bus.
  [5] L2OCRAM_BANK4_BUS_SAFETY_FI_DED — Set this bit to 1'b1 inject ded error on data at this port
  [4] L2OCRAM_BANK4_BUS_SAFETY_FI_SEC — Set this bit to 1'b1 to inject sec error on data at this port
  [3] L2OCRAM_BANK4_BUS_SAFETY_FI_GLOBAL_SAFE_REQ — Set this bit 1'b1 to inject fault for request signals on Safe Interconnect.
  [2] L2OCRAM_BANK4_BUS_SAFETY_FI_GLOBAL_MAIN_REQ — Set this bit to 1'b1 to inject fault for request signals on main Interconnect.
  [1] L2OCRAM_BANK4_BUS_SAFETY_FI_GLOBAL_SAFE — This is a global safe Fault injection signal. Set this bit to inject fault on all the safety buses of the safe interconnect except req signal. Writing a 1'b1 injects fault on interconnect.
  [0] L2OCRAM_BANK4_BUS_SAFETY_FI_GLOBAL_MAIN — This is a global main Fault injection signal. Set this bit to inject fault on all the buses of the main interconnect except req signal. Writing a 1'b1 injects fault on interconnect.
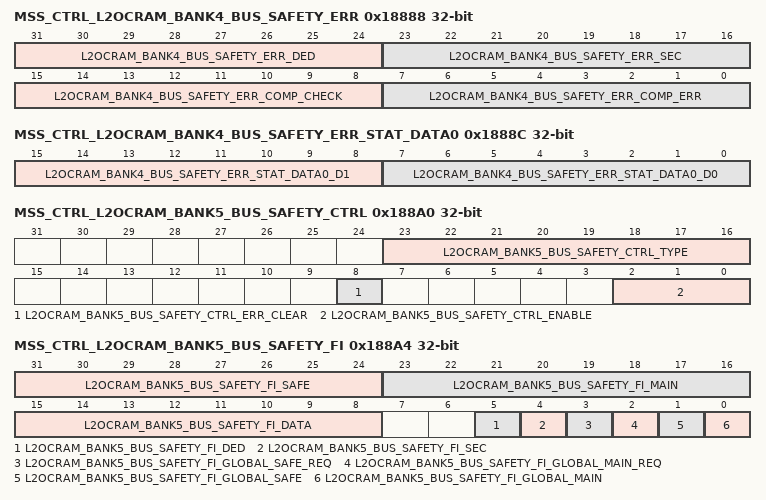
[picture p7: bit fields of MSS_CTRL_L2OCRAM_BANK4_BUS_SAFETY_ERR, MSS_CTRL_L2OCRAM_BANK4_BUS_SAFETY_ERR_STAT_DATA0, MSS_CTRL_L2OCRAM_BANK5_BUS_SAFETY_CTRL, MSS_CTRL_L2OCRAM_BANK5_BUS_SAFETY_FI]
0x18888 MSS_CTRL_L2OCRAM_BANK4_BUS_SAFETY_ERR ro
  [31:24] L2OCRAM_BANK4_BUS_SAFETY_ERR_DED — This flag signals detection of dual error in Data at this port.Flag is generted for 32 bit segment of Data BusBit 0 - 1'b1 indicates ded on [31:0] bit of Data busBit 1 - 1'b1 indicates ded on [63:32] bit of Data busBit [7:2] - Unused. Set to 1'b0
  [23:16] L2OCRAM_BANK4_BUS_SAFETY_ERR_SEC — This flag signals detection of single error in Data at this port. Flag is generted for 32 bit segment of Data BusBit 0 - 1'b1 indicates sec on [31:0] bit of Data busBit 1 - 1'b1 indicates sec on [63:32] bit of Data busBit [7:2] - Unused. Set to 1'b0
  [15:8] L2OCRAM_BANK4_BUS_SAFETY_ERR_COMP_CHECK — This is used to verify the proper functioning of fault Injection on all the buses.1'b1 indicates error in the corresponding Bus has been injected successfully. Bit 0 - This is a Bitwise AND of error compares of all command bus signals.Bit 1 - This is a Bitwise AND of error compares of all write bus signals.Bit 2 - This is a Bitwise AND of error compares of all write status bus signals.Bit 3 - This is a Bitwise AND of error compares of all read bus signals.Bits [7:4] are unused.
  [7:0] L2OCRAM_BANK4_BUS_SAFETY_ERR_COMP_ERR — 1'b1 indicates error in the corresponding Bus whenever a fault is detected at any bus signalBit 0 - This is a Bitwise OR of error compares of all command bus signals.Bit 1 - This is a Bitwise OR of error compares of all write bus signals.Bit 2 - This is a Bitwise OR of error compares of all write status bus signals.Bit 3 - This is a Bitwise OR of error compares of all read bus signals.Bits [7:4] are unused.
0x1888C MSS_CTRL_L2OCRAM_BANK4_BUS_SAFETY_ERR_STAT_DATA0 ro
  [15:8] L2OCRAM_BANK4_BUS_SAFETY_ERR_STAT_DATA0_D1 — Read this bitfield for Comparator status for Higher 32 bits [63:32] of data bus at this port. It represent the position of the flipped bit in case of SEC.
  [7:0] L2OCRAM_BANK4_BUS_SAFETY_ERR_STAT_DATA0_D0 — Read this bitfield for Comparator status for lower 32 bits [31:0] of data bus at this port. It represent the position of the flipped bit in case of SEC.
0x18890 MSS_CTRL_L2OCRAM_BANK4_BUS_SAFETY_ERR_STAT_CMD ro
  [31:0] L2OCRAM_BANK4_BUS_SAFETY_ERR_STAT_CMD_STAT — Read this bitfield for comparator status for command bus for this port. 1'b1 on any of the bits indicates an error on Command Bus
0x18894 MSS_CTRL_L2OCRAM_BANK4_BUS_SAFETY_ERR_STAT_WRITE ro
  [31:0] L2OCRAM_BANK4_BUS_SAFETY_ERR_STAT_WRITE_STAT — Read this bitfield for comparator status for Write bus for this port. 1'b1 at any bit indicates error on Write Bus
0x18898 MSS_CTRL_L2OCRAM_BANK4_BUS_SAFETY_ERR_STAT_READ ro
  [31:0] L2OCRAM_BANK4_BUS_SAFETY_ERR_STAT_READ_STAT — Read this bitfield for comapartor status for read signals at this port. 1'b1 on any of the bits indicates an error on Read bus.
0x1889C MSS_CTRL_L2OCRAM_BANK4_BUS_SAFETY_ERR_STAT_WRITERESP ro
  [31:0] L2OCRAM_BANK4_BUS_SAFETY_ERR_STAT_WRITERESP_STAT — Read this bitfield for comparator status for Write response bus for this port. 1'b1 indicates error on Write Rsponse Bus.
0x188A0 MSS_CTRL_L2OCRAM_BANK5_BUS_SAFETY_CTRL access per field
  [23:16] L2OCRAM_BANK5_BUS_SAFETY_CTRL_TYPE ro — This bitfield gives a top level idea of the available bus [cmd,wr,ws,rd] for the particular Target/Initiator and whether it follows the VBUS protocol or not. Bit 0 - 1'b1 indicates the Command bus is implemented to this target/initiator else it is set to 1'b0. Bit 1 - 1'b1 indicates the write bus is implemented to this target/initiator else it is set to 1'b0. Bit 2 - 1'b1 indicates the write status bus is implemented to this target/initiator else it is set to 1'b0. Bit 3 - 1'b1 indicates the read bus is implemented to this target/initiator else it is set to 1'b0. Bit 4 - 1'b0 indicates the port follows the VBUS protocol else it is set to 1'b1. Bits 5-7 are set to 3'b000.
  [8] L2OCRAM_BANK5_BUS_SAFETY_CTRL_ERR_CLEAR rw — Set this bit to 1'b1 to clear the error status for this port
  [2:0] L2OCRAM_BANK5_BUS_SAFETY_CTRL_ENABLE rw — Set this bit to 3'b111 to enable the safety configuration for this port. Set this bit to 3'b000 to disable the safety configuration for this port.
0x188A4 MSS_CTRL_L2OCRAM_BANK5_BUS_SAFETY_FI
  [31:24] L2OCRAM_BANK5_BUS_SAFETY_FI_SAFE — This bitfield is used to inject fault on Read, write, command and request bus on the safe Interconnect. Bit 0 - Set this bit to inject fault on the Command bus. Bit 1 - Set this bit to inject fault on theWrite bus. Bit 2 - Set this bit to inject fault on the Write Status bus.Bit 3 - Set this bit to inject fault on the Read bus. Bit 7- Set this bit to inject fault on the corresponding request bus.
  [23:16] L2OCRAM_BANK5_BUS_SAFETY_FI_MAIN — This bitfield is used to inject fault on Read, write, command and request bus on the main Interconnect.Bit 0 - Set this bit to inject fault on the Command bus. Bit 1 - Set this bit to inject fault on theWrite bus. Bit 2 - Set this bit to inject fault on the Write Status bus.Bit 3 - Set this bit to inject fault on the Read bus. Bit 7- Set this bit to inject fault on the corresponding request bus.
  [15:8] L2OCRAM_BANK5_BUS_SAFETY_FI_DATA — Set bit 0 to 1'b1 to inject sec and ded faults on [31:0] bits of data bus.Set bit 1 to 1'b1 to inject sec and ded faults on [64:32] bits of data bus.
  [5] L2OCRAM_BANK5_BUS_SAFETY_FI_DED — Set this bit to 1'b1 inject ded error on data at this port
  [4] L2OCRAM_BANK5_BUS_SAFETY_FI_SEC — Set this bit to 1'b1 to inject sec error on data at this port
  [3] L2OCRAM_BANK5_BUS_SAFETY_FI_GLOBAL_SAFE_REQ — Set this bit 1'b1 to inject fault for request signals on Safe Interconnect.
  [2] L2OCRAM_BANK5_BUS_SAFETY_FI_GLOBAL_MAIN_REQ — Set this bit to 1'b1 to inject fault for request signals on main Interconnect.
  [1] L2OCRAM_BANK5_BUS_SAFETY_FI_GLOBAL_SAFE — This is a global safe Fault injection signal. Set this bit to inject fault on all the safety buses of the safe interconnect except req signal. Writing a 1'b1 injects fault on interconnect.
  [0] L2OCRAM_BANK5_BUS_SAFETY_FI_GLOBAL_MAIN — This is a global main Fault injection signal. Set this bit to inject fault on all the buses of the main interconnect except req signal. Writing a 1'b1 injects fault on interconnect.
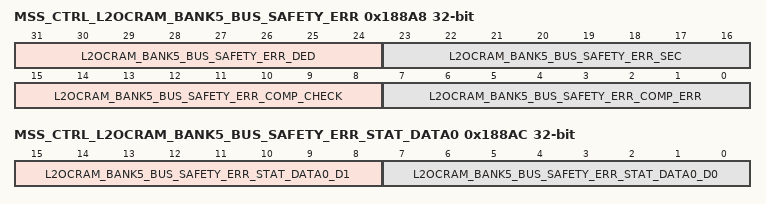
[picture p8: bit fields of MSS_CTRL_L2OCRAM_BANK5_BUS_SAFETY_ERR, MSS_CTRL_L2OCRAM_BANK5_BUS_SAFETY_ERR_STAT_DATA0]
0x188A8 MSS_CTRL_L2OCRAM_BANK5_BUS_SAFETY_ERR ro
  [31:24] L2OCRAM_BANK5_BUS_SAFETY_ERR_DED — This flag signals detection of dual error in Data at this port.Flag is generted for 32 bit segment of Data BusBit 0 - 1'b1 indicates ded on [31:0] bit of Data busBit 1 - 1'b1 indicates ded on [63:32] bit of Data busBit [7:2] - Unused. Set to 1'b0
  [23:16] L2OCRAM_BANK5_BUS_SAFETY_ERR_SEC — This flag signals detection of single error in Data at this port. Flag is generted for 32 bit segment of Data BusBit 0 - 1'b1 indicates sec on [31:0] bit of Data busBit 1 - 1'b1 indicates sec on [63:32] bit of Data busBit [7:2] - Unused. Set to 1'b0
  [15:8] L2OCRAM_BANK5_BUS_SAFETY_ERR_COMP_CHECK — This is used to verify the proper functioning of fault Injection on all the buses.1'b1 indicates error in the corresponding Bus has been injected successfully. Bit 0 - This is a Bitwise AND of error compares of all command bus signals.Bit 1 - This is a Bitwise AND of error compares of all write bus signals.Bit 2 - This is a Bitwise AND of error compares of all write status bus signals.Bit 3 - This is a Bitwise AND of error compares of all read bus signals.Bits [7:4] are unused.
  [7:0] L2OCRAM_BANK5_BUS_SAFETY_ERR_COMP_ERR — 1'b1 indicates error in the corresponding Bus whenever a fault is detected at any bus signalBit 0 - This is a Bitwise OR of error compares of all command bus signals.Bit 1 - This is a Bitwise OR of error compares of all write bus signals.Bit 2 - This is a Bitwise OR of error compares of all write status bus signals.Bit 3 - This is a Bitwise OR of error compares of all read bus signals.Bits [7:4] are unused.
0x188AC MSS_CTRL_L2OCRAM_BANK5_BUS_SAFETY_ERR_STAT_DATA0 ro
  [15:8] L2OCRAM_BANK5_BUS_SAFETY_ERR_STAT_DATA0_D1 — Read this bitfield for Comparator status for Higher 32 bits [63:32] of data bus at this port. It represent the position of the flipped bit in case of SEC.
  [7:0] L2OCRAM_BANK5_BUS_SAFETY_ERR_STAT_DATA0_D0 — Read this bitfield for Comparator status for lower 32 bits [31:0] of data bus at this port. It represent the position of the flipped bit in case of SEC.
0x188B0 MSS_CTRL_L2OCRAM_BANK5_BUS_SAFETY_ERR_STAT_CMD ro
  [31:0] L2OCRAM_BANK5_BUS_SAFETY_ERR_STAT_CMD_STAT — Read this bitfield for comparator status for command bus for this port. 1'b1 on any of the bits indicates an error on Command Bus
0x188B4 MSS_CTRL_L2OCRAM_BANK5_BUS_SAFETY_ERR_STAT_WRITE ro
  [31:0] L2OCRAM_BANK5_BUS_SAFETY_ERR_STAT_WRITE_STAT — Read this bitfield for comparator status for Write bus for this port. 1'b1 at any bit indicates error on Write Bus
0x188B8 MSS_CTRL_L2OCRAM_BANK5_BUS_SAFETY_ERR_STAT_READ ro
  [31:0] L2OCRAM_BANK5_BUS_SAFETY_ERR_STAT_READ_STAT — Read this bitfield for comapartor status for read signals at this port. 1'b1 on any of the bits indicates an error on Read bus.
0x188BC MSS_CTRL_L2OCRAM_BANK5_BUS_SAFETY_ERR_STAT_WRITERESP ro
  [31:0] L2OCRAM_BANK5_BUS_SAFETY_ERR_STAT_WRITERESP_STAT — Read this bitfield for comparator status for Write response bus for this port. 1'b1 indicates error on Write Rsponse Bus.
